# bao1x register map
Vendor: baochip; File version: 1.0
Registers are 32-bit, read-write, reset 0x0 unless marked. A register's access mark holds for its fields unless they carry their own. Offsets are from the block's base; [hi:lo] are bit positions; {n}, {i} and the like mark numbered series; <NAME> marks a mode.

## ALU
Base 0x4002F000
0x00 SFR_CRFUNC — See `alu.sv#L136 <https://github.com/baochip/baochip-1x/blob/main/rtl/modules/cr ypto_alu/rtl/alu.sv#L136>`__ (line numbers are approximate)
  [7:0] sfr_crfunc — sfr_crfunc read/write control register
0x04 SFR_AR — See `alu.sv#L137 <https://github.com/baochip/baochip-1x/blob/main/rtl/modules/cr ypto_alu/rtl/alu.sv#L137>`__ (line numbers are approximate)
  [31:0] sfr_ar — sfr_ar performs action on write of value: 0x5a
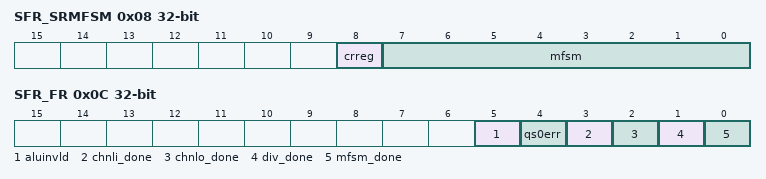
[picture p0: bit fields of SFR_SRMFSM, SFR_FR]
0x08 SFR_SRMFSM — See `alu.sv#L138 <https://github.com/baochip/baochip-1x/blob/main/rtl/modules/cr ypto_alu/rtl/alu.sv#L138>`__ (line numbers are approximate)
  [8] crreg — crreg read only status register
  [7:0] mfsm — mfsm read only status register
0x0C SFR_FR — See `alu.sv#L139 <https://github.com/baochip/baochip-1x/blob/main/rtl/modules/cr ypto_alu/rtl/alu.sv#L139>`__ (line numbers are approximate)
  [5] aluinvld — aluinvld flag register. `1` means event happened, write back `1` in respective bit position to clear the flag
  [4] qs0err — qs0err flag register. `1` means event happened, write back `1` in respective bit position to clear the flag
  [3] chnli_done — chnli_done flag register. `1` means event happened, write back `1` in respective bit position to clear the flag
  [2] chnlo_done — chnlo_done flag register. `1` means event happened, write back `1` in respective bit position to clear the flag
  [1] div_done — div_done flag register. `1` means event happened, write back `1` in respective bit position to clear the flag
  [0] mfsm_done — mfsm_done flag register. `1` means event happened, write back `1` in respective bit position to clear the flag
0x10 SFR_CRDIVLEN — See `alu.sv#L141 <https://github.com/baochip/baochip-1x/blob/main/rtl/modules/cr ypto_alu/rtl/alu.sv#L141>`__ (line numbers are approximate)
  [15:0] sfr_crdivlen — sfr_crdivlen read/write control register
0x14 SFR_SRDIVLEN — See `alu.sv#L142 <https://github.com/baochip/baochip-1x/blob/main/rtl/modules/cr ypto_alu/rtl/alu.sv#L142>`__ (line numbers are approximate)
  [15:0] sfr_srdivlen — sfr_srdivlen read only status register
0x18 SFR_OPT — See `alu.sv#L143 <https://github.com/baochip/baochip-1x/blob/main/rtl/modules/cr ypto_alu/rtl/alu.sv#L143>`__ (line numbers are approximate)
  [31:0] sfr_opt — sfr_opt read/write control register
0x1C SFR_OPTLTX — See `alu.sv#L144 <https://github.com/baochip/baochip-1x/blob/main/rtl/modules/cr ypto_alu/rtl/alu.sv#L144>`__ (line numbers are approximate)
  [7:0] sfr_optltx — sfr_optltx read/write control register
{0x30+4i} SFR_SEGPTR_CR_SEGCFG{i} (i=0..3) — See `alu.sv#L146 <https://github.com/baochip/baochip-1x/blob/main/rtl/modules/cr ypto_alu/rtl/alu.sv#L146>`__ (line numbers are approximate)
  [19:0] cr_segcfg{i} — cr_segcfg read/write control register

## AES
Base 0x4002D000
0x00 SFR_CRFUNC — See `aes.sv#L140 <https://github.com/baochip/baochip-1x/blob/main/rtl/modules/cr ypto_top/rtl/aes.sv#L140>`__ (line numbers are approximate)
  [7:0] sfr_crfunc — sfr_crfunc read/write control register
0x04 SFR_AR — See `aes.sv#L141 <https://github.com/baochip/baochip-1x/blob/main/rtl/modules/cr ypto_top/rtl/aes.sv#L141>`__ (line numbers are approximate)
  [31:0] sfr_ar — sfr_ar performs action on write of value: 0x5a
0x08 SFR_SRMFSM — See `aes.sv#L142 <https://github.com/baochip/baochip-1x/blob/main/rtl/modules/cr ypto_top/rtl/aes.sv#L142>`__ (line numbers are approximate)
  [7:0] sfr_srmfsm — sfr_srmfsm read only status register
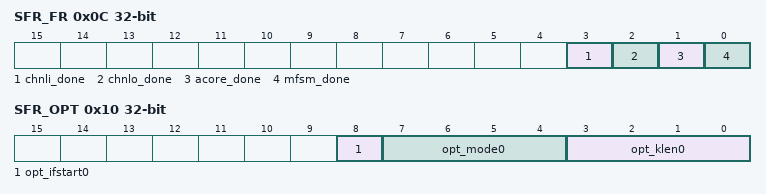
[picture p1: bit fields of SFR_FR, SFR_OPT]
0x0C SFR_FR — See `aes.sv#L143 <https://github.com/baochip/baochip-1x/blob/main/rtl/modules/cr ypto_top/rtl/aes.sv#L143>`__ (line numbers are approximate)
  [3] chnli_done — chnli_done flag register. `1` means event happened, write back `1` in respective bit position to clear the flag
  [2] chnlo_done — chnlo_done flag register. `1` means event happened, write back `1` in respective bit position to clear the flag
  [1] acore_done — acore_done flag register. `1` means event happened, write back `1` in respective bit position to clear the flag
  [0] mfsm_done — mfsm_done flag register. `1` means event happened, write back `1` in respective bit position to clear the flag
0x10 SFR_OPT — See `aes.sv#L145 <https://github.com/baochip/baochip-1x/blob/main/rtl/modules/cr ypto_top/rtl/aes.sv#L145>`__ (line numbers are approximate)
  [8] opt_ifstart0 — opt_ifstart0 read/write control register
  [7:4] opt_mode0 — opt_mode0 read/write control register
  [3:0] opt_klen0 — opt_klen0 read/write control register
0x14 SFR_OPT1 — See `aes.sv#L146 <https://github.com/baochip/baochip-1x/blob/main/rtl/modules/cr ypto_top/rtl/aes.sv#L146>`__ (line numbers are approximate)
  [15:0] sfr_opt1 — sfr_opt1 read/write control register
0x18 SFR_OPTLTX — See `aes.sv#L147 <https://github.com/baochip/baochip-1x/blob/main/rtl/modules/cr ypto_top/rtl/aes.sv#L147>`__ (line numbers are approximate)
  [5:0] sfr_optltx — sfr_optltx read/write control register
0x20 SFR_MASKSEED — See `aes.sv#L150 <https://github.com/baochip/baochip-1x/blob/main/rtl/modules/cr ypto_top/rtl/aes.sv#L150>`__ (line numbers are approximate)
  [31:0] sfr_maskseed — sfr_maskseed read/write control register
0x24 SFR_MASKSEEDAR — See `aes.sv#L151 <https://github.com/baochip/baochip-1x/blob/main/rtl/modules/cr ypto_top/rtl/aes.sv#L151>`__ (line numbers are approximate)
  [31:0] sfr_maskseedar — sfr_maskseedar performs action on write of value: 0x5a
0x30 SFR_SEGPTR_PTRID_IV — See `aes.sv#L153 <https://github.com/baochip/baochip-1x/blob/main/rtl/modules/cr ypto_top/rtl/aes.sv#L153>`__ (line numbers are approximate)
  [11:0] PTRID_IV — cr_segptrstart read/write control register
0x34 SFR_SEGPTR_PTRID_AKEY — See `aes.sv#L153 <https://github.com/baochip/baochip-1x/blob/main/rtl/modules/cr ypto_top/rtl/aes.sv#L153>`__ (line numbers are approximate)
  [11:0] PTRID_AKEY — cr_segptrstart read/write control register
0x38 SFR_SEGPTR_PTRID_AIB — See `aes.sv#L153 <https://github.com/baochip/baochip-1x/blob/main/rtl/modules/cr ypto_top/rtl/aes.sv#L153>`__ (line numbers are approximate)
  [11:0] PTRID_AIB — cr_segptrstart read/write control register
0x3C SFR_SEGPTR_PTRID_AOB — See `aes.sv#L153 <https://github.com/baochip/baochip-1x/blob/main/rtl/modules/cr ypto_top/rtl/aes.sv#L153>`__ (line numbers are approximate)
  [11:0] PTRID_AOB — cr_segptrstart read/write control register
